# ESP32-C2 register map
Vendor: ESPRESSIF SYSTEMS (SHANGHAI) CO., LTD.; Series: ESP32 C-Series; File version: 11
CPU: RV32IMC r0p0, little endian, no MPU, no FPU, 0 interrupt priority bits
Address unit: 32 bits
Registers are 32-bit, read-write, reset 0x0 unless marked. A register's access mark holds for its fields unless they carry their own. Offsets are from the block's base; [hi:lo] are bit positions; {n}, {i} and the like mark numbered series.

## SYSTEM — System Configuration Registers
Base 0x600C0000
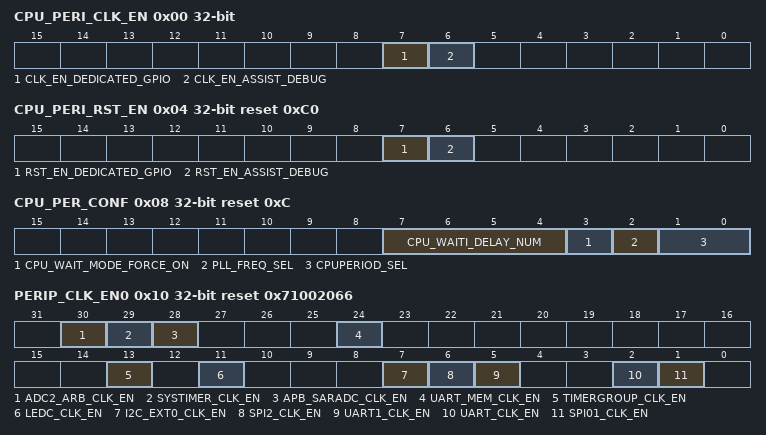
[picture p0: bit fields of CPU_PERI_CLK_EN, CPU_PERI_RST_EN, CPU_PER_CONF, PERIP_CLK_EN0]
0x00 CPU_PERI_CLK_EN — cpu_peripheral clock gating register
  [7] CLK_EN_DEDICATED_GPIO — Set 1 to open dedicated_gpio module clk
  [6] CLK_EN_ASSIST_DEBUG — Set 1 to open assist_debug module clock
0x04 CPU_PERI_RST_EN reset 0xC0 — cpu_peripheral reset register
  [7] RST_EN_DEDICATED_GPIO — Set 1 to let dedicated_gpio module reset
  [6] RST_EN_ASSIST_DEBUG — Set 1 to let assist_debug module reset
0x08 CPU_PER_CONF reset 0xC — cpu clock config register
  [7:4] CPU_WAITI_DELAY_NUM — This field used to set delay cycle when cpu enter waiti mode, after delay waiti_clk will close
  [3] CPU_WAIT_MODE_FORCE_ON — Set 1 to force cpu_waiti_clk enable.
  [2] PLL_FREQ_SEL — This field used to sel pll frequent.
  [1:0] CPUPERIOD_SEL — This field used to sel cpu clock frequent.
0x0C MEM_PD_MASK reset 0x1 — memory power down mask register
  [0] LSLP_MEM_PD_MASK — Set 1 to mask memory power down.
0x10 PERIP_CLK_EN0 reset 0x71002066 — peripheral clock gating register
  [30] ADC2_ARB_CLK_EN — Set 1 to enable ADC2_ARB clock
  [29] SYSTIMER_CLK_EN — Set 1 to enable SYSTEMTIMER clock
  [28] APB_SARADC_CLK_EN — Set 1 to enable APB_SARADC clock
  [24] UART_MEM_CLK_EN — Set 1 to enable UART_MEM clock
  [13] TIMERGROUP_CLK_EN — Set 1 to enable TIMERGROUP clock
  [11] LEDC_CLK_EN — Set 1 to enable LEDC clock
  [7] I2C_EXT0_CLK_EN — Set 1 to enable I2C_EXT0 clock
  [6] SPI2_CLK_EN — Set 1 to enable SPI2 clock
  [5] UART1_CLK_EN — Set 1 to enable UART1 clock
  [2] UART_CLK_EN — Set 1 to enable UART clock
  [1] SPI01_CLK_EN — Set 1 to enable SPI01 clock
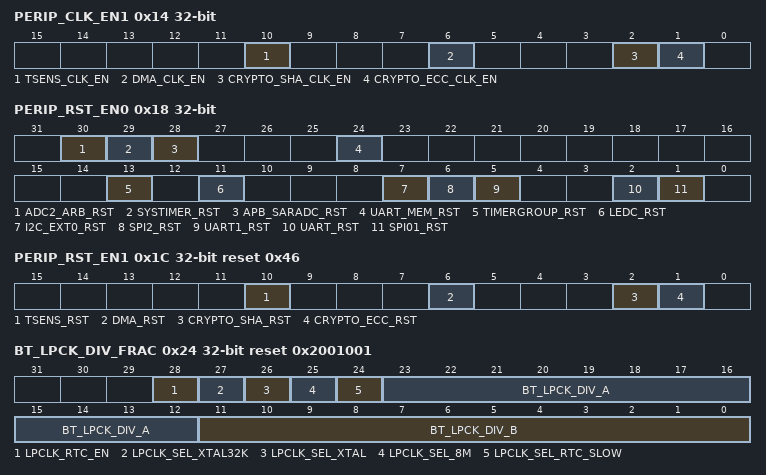
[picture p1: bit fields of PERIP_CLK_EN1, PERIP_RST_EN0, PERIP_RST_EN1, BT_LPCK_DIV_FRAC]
0x14 PERIP_CLK_EN1 — peripheral clock gating register
  [10] TSENS_CLK_EN — Set 1 to enable TSENS clock
  [6] DMA_CLK_EN — Set 1 to enable DMA clock
  [2] CRYPTO_SHA_CLK_EN — Set 1 to enable SHA clock
  [1] CRYPTO_ECC_CLK_EN — Set 1 to enable ECC clock
0x18 PERIP_RST_EN0 — reserved
  [30] ADC2_ARB_RST — Set 1 to let ADC2_ARB reset
  [29] SYSTIMER_RST — Set 1 to let SYSTIMER reset
  [28] APB_SARADC_RST — Set 1 to let APB_SARADC reset
  [24] UART_MEM_RST — Set 1 to let UART_MEM reset
  [13] TIMERGROUP_RST — Set 1 to let TIMERGROUP reset
  [11] LEDC_RST — Set 1 to let LEDC reset
  [7] I2C_EXT0_RST — Set 1 to let I2C_EXT0 reset
  [6] SPI2_RST — Set 1 to let SPI2 reset
  [5] UART1_RST — Set 1 to let UART1 reset
  [2] UART_RST — Set 1 to let UART reset
  [1] SPI01_RST — Set 1 to let SPI01 reset
0x1C PERIP_RST_EN1 reset 0x46 — peripheral reset register
  [10] TSENS_RST — Set 1 to let TSENS reset
  [6] DMA_RST — Set 1 to let DMA reset
  [2] CRYPTO_SHA_RST — Set 1 to let CRYPTO_SHA reset
  [1] CRYPTO_ECC_RST — Set 1 to let CRYPTO_ECC reset
0x20 BT_LPCK_DIV_INT reset 0xFF — clock config register
  [11:0] BT_LPCK_DIV_NUM — This field is lower power clock frequent division factor
0x24 BT_LPCK_DIV_FRAC reset 0x2001001 — low power clock configuration register
  [28] LPCLK_RTC_EN — Set 1 to enable RTC low power clock
  [27] LPCLK_SEL_XTAL32K — Set 1 to select xtal32k clock as low power clock
  [26] LPCLK_SEL_XTAL — Set 1 to select xtal clock as rtc low power clock
  [25] LPCLK_SEL_8M — Set 1 to select 8m clock as rtc low power clock
  [24] LPCLK_SEL_RTC_SLOW — Set 1 to select rtc-slow clock as rtc low power clock
  [23:12] BT_LPCK_DIV_A — This field is lower power clock frequent division factor a
  [11:0] BT_LPCK_DIV_B — This field is lower power clock frequent division factor b
{0x28+4i} CPU_INTR_FROM_CPU_{i} (i=0..3) — interrupt generate register
  [0] CPU_INTR_FROM_CPU_{i} — Set 1 to generate cpu interrupt {i}
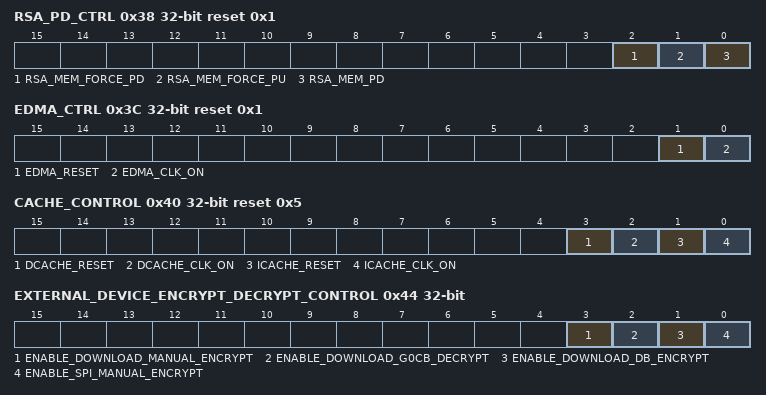
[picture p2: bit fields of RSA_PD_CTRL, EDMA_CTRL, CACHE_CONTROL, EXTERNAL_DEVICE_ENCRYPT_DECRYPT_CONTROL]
0x38 RSA_PD_CTRL reset 0x1 — rsa memory power control register
  [2] RSA_MEM_FORCE_PD — Set 1 to force power down RSA memory. This bit has the highest priority.
  [1] RSA_MEM_FORCE_PU — Set 1 to force power up RSA memory. This bit has the second highest priority.
  [0] RSA_MEM_PD — Set 1 to power down RSA memory. This bit has the lowest priority.When Digital Signature occupies the RSA. This bit is invalid.
0x3C EDMA_CTRL reset 0x1 — edma clcok and reset register
  [1] EDMA_RESET — Set 1 to let EDMA reset
  [0] EDMA_CLK_ON — Set 1 to enable EDMA clock.
0x40 CACHE_CONTROL reset 0x5
  [3] DCACHE_RESET — Set 1 to let dcache reset
  [2] DCACHE_CLK_ON — Set 1 to enable dcache clock
  [1] ICACHE_RESET — Set 1 to let icache reset
  [0] ICACHE_CLK_ON — Set 1 to enable icache clock
0x44 EXTERNAL_DEVICE_ENCRYPT_DECRYPT_CONTROL — SYSTEM_EXTERNAL_DEVICE_ENCRYPT_DECRYPT_CONTROL_REG
  [3] ENABLE_DOWNLOAD_MANUAL_ENCRYPT — Set 1 to enable download manual encrypt
  [2] ENABLE_DOWNLOAD_G0CB_DECRYPT — Set 1 to enable download G0CB decrypt
  [1] ENABLE_DOWNLOAD_DB_ENCRYPT — Set 1 to enable download DB encrypt.
  [0] ENABLE_SPI_MANUAL_ENCRYPT — Set 1 to enable the SPI manual encrypt.
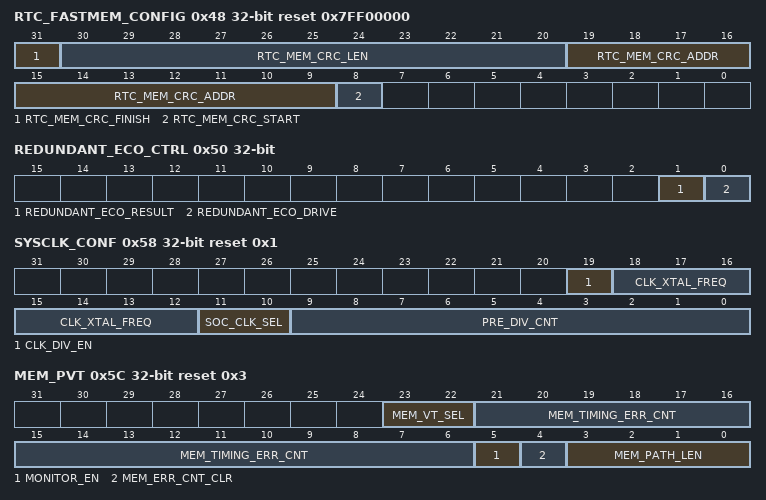
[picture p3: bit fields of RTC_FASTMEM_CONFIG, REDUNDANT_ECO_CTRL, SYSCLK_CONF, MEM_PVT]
0x48 RTC_FASTMEM_CONFIG access per field reset 0x7FF00000 — fast memory config register
  [31] RTC_MEM_CRC_FINISH ro — This bit stores the status of RTC memory CRC.1 means finished.
  [30:20] RTC_MEM_CRC_LEN rw — This field is used to set length of RTC memory for CRC based on start address.
  [19:9] RTC_MEM_CRC_ADDR rw — This field is used to set address of RTC memory for CRC.
  [8] RTC_MEM_CRC_START rw — Set 1 to start the CRC of RTC memory
0x4C RTC_FASTMEM_CRC ro — reserved
  [31:0] RTC_MEM_CRC_RES — This field stores the CRC result of RTC memory.
0x50 REDUNDANT_ECO_CTRL access per field — eco register
  [1] REDUNDANT_ECO_RESULT ro — reg_redundant_eco_result
  [0] REDUNDANT_ECO_DRIVE rw — reg_redundant_eco_drive
0x54 CLOCK_GATE reset 0x1 — clock gating register
  [0] CLK_EN — reg_clk_en
0x58 SYSCLK_CONF access per field reset 0x1 — system clock config register
  [19] CLK_DIV_EN ro — reg_clk_div_en
  [18:12] CLK_XTAL_FREQ ro — This field is used to read xtal frequency in MHz.
  [11:10] SOC_CLK_SEL rw — This field is used to select soc clock.
  [9:0] PRE_DIV_CNT rw — This field is used to set the count of prescaler of XTAL_CLK.
0x5C MEM_PVT access per field reset 0x3
  [23:22] MEM_VT_SEL rw — reg_mem_vt_sel
  [21:6] MEM_TIMING_ERR_CNT ro — reg_mem_timing_err_cnt
  [5] MONITOR_EN rw — reg_mem_pvt_monitor_en
  [4] MEM_ERR_CNT_CLR wo — reg_mem_err_cnt_clr
  [3:0] MEM_PATH_LEN rw — reg_mem_path_len
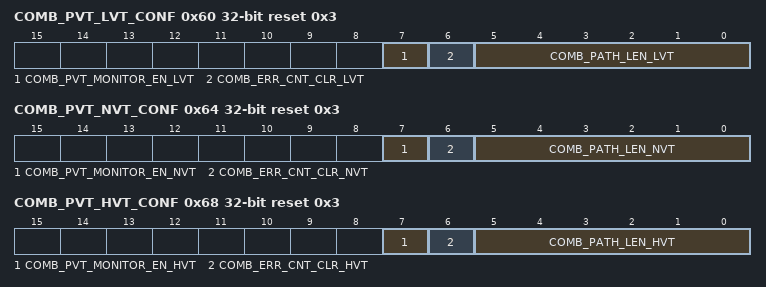
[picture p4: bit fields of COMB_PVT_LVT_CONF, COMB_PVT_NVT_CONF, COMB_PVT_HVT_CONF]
0x60 COMB_PVT_LVT_CONF access per field reset 0x3 — mem pvt register
  [7] COMB_PVT_MONITOR_EN_LVT rw — reg_comb_pvt_monitor_en_lvt
  [6] COMB_ERR_CNT_CLR_LVT wo — reg_comb_err_cnt_clr_lvt
  [5:0] COMB_PATH_LEN_LVT rw — reg_comb_path_len_lvt
0x64 COMB_PVT_NVT_CONF access per field reset 0x3 — mem pvt register
  [7] COMB_PVT_MONITOR_EN_NVT rw — reg_comb_pvt_monitor_en_nvt
  [6] COMB_ERR_CNT_CLR_NVT wo — reg_comb_err_cnt_clr_nvt
  [5:0] COMB_PATH_LEN_NVT rw — reg_comb_path_len_nvt
0x68 COMB_PVT_HVT_CONF access per field reset 0x3 — mem pvt register
  [7] COMB_PVT_MONITOR_EN_HVT rw — reg_comb_pvt_monitor_en_hvt
  [6] COMB_ERR_CNT_CLR_HVT wo — reg_comb_err_cnt_clr_hvt
  [5:0] COMB_PATH_LEN_HVT rw — reg_comb_path_len_hvt
{0x6C+0xC*i} COMB_PVT_ERR_LVT_SITE{i} ro (i=0..3) — mem pvt register
  [15:0] COMB_TIMING_ERR_CNT_LVT_SITE{i} — reg_comb_timing_err_cnt_lvt_site{i}
{0x70+0xC*i} COMB_PVT_ERR_NVT_SITE{i} ro (i=0..3) — mem pvt register
  [15:0] COMB_TIMING_ERR_CNT_NVT_SITE{i} — reg_comb_timing_err_cnt_nvt_site{i}
{0x74+0xC*i} COMB_PVT_ERR_HVT_SITE{i} ro (i=0..3) — mem pvt register
  [15:0] COMB_TIMING_ERR_CNT_HVT_SITE{i} — reg_comb_timing_err_cnt_hvt_site{i}
0xFFC REG_DATE reset 0x2108190 — Version register
  [27:0] SYSTEM_REG_DATE — reg_system_reg_date
